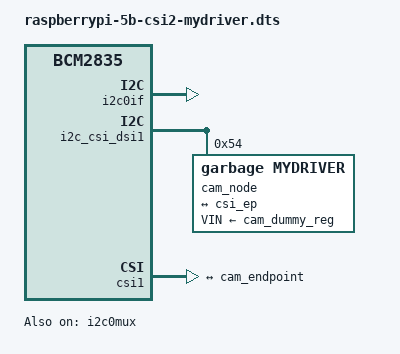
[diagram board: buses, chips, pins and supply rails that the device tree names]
// SPDX-License-Identifier: GPL-2.0-only
/dts-v1/;
/plugin/;

#include <gpio.h>

/{
	compatible = "brcm,bcm2835";

	fragment@0 {
		target = <&i2c0if>;
		__overlay__ {
			status = "okay";
		};
	};

	fragment@2 {
		target = <&i2c0mux>;
		__overlay__ {
			status = "okay";
		};
	};

	i2c_frag: fragment@100 {
		target = <&i2c_csi_dsi1>;
		__overlay__ {
			#address-cells = <1>;
			#size-cells = <0>;
			status = "okay";

			// For imx219 that piece is included
			cam_node: mydriver@54 {
				compatible = "garbage,mydriver";
				reg = <0x54>;
				status = "disabled";

				VIN-supply = <&cam_dummy_reg>;	/* 5.1v, not fed from RPi 5 */

				orientation = <2>;

				port {
					cam_endpoint: endpoint {
						clock-lanes = <0>;
						data-lanes = <1 2 3 4>;
						clock-continuous;
						link-frequencies =
							/bits/ 64 <100000000>;
					};
				};
			};
		};
	};

	csi_frag: fragment@101 {
		target = <&csi1>;
		csi: __overlay__ {
			status = "okay";
			brcm,media-controller;

			port {
				csi_ep: endpoint {
					remote-endpoint = <&cam_endpoint>;
					clock-lanes = <0>;
					data-lanes = <1 2 3 4>;
					clock-continuous;
				};
			};
		};
	};

	__overrides__ {
		rotation = <&cam_node>,"rotation:0";
		orientation = <&cam_node>,"orientation:0";
		media-controller = <&csi>,"brcm,media-controller?";
		cam0 = <&i2c_frag>, "target:0=",<&i2c_csi_dsi0>,
		       <&csi_frag>, "target:0=",<&csi0>,
		       <&cam_node>, "VIN-supply:0=",<&cam0_reg>;
	};
};

&cam_node {
	status = "okay";
};

&cam_endpoint {
	remote-endpoint = <&csi_ep>;
};
